# rp2040 register map
Vendor: Raspberry Pi; File version: 0.1
CPU: CM0PLUS r0p1, little endian, MPU, no FPU, VTOR, 2 interrupt priority bits, 26 interrupts
Registers are 32-bit, read-write, reset 0x0 unless marked. A register's access mark holds for its fields unless they carry their own. Offsets are from the block's base; [hi:lo] are bit positions; {n}, {i} and the like mark numbered series; 'fields as' and 'values as' point back to an identical list.

## SYSCFG — Register block for various chip control signals
Base 0x40004000
0x00 PROC0_NMI_MASK — Processor core 0 NMI source mask. Set a bit high to enable NMI from that IRQ
0x04 PROC1_NMI_MASK — Processor core 1 NMI source mask. Set a bit high to enable NMI from that IRQ
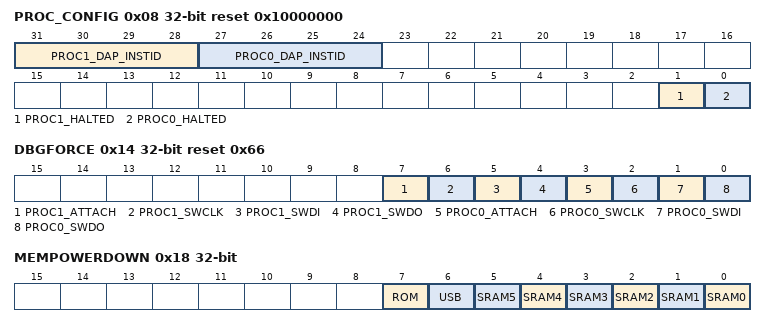
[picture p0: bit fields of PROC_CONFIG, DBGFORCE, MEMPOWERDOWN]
0x08 PROC_CONFIG access per field reset 0x10000000 — Configuration for processors
  [31:28] PROC1_DAP_INSTID rw — Configure proc1 DAP instance ID. Recommend that this is NOT changed until you require debug access in multi-chip environment. WARNING: do not set to 15 as this is reserved for RescueDP
  [27:24] PROC0_DAP_INSTID rw — Configure proc0 DAP instance ID. Recommend that this is NOT changed until you require debug access in multi-chip environment. WARNING: do not set to 15 as this is reserved for RescueDP
  [1] PROC1_HALTED ro — Indication that proc1 has halted
  [0] PROC0_HALTED ro — Indication that proc0 has halted
0x0C PROC_IN_SYNC_BYPASS — For each bit, if 1, bypass the input synchronizer between that GPIO and the GPIO input register in the SIO. The input synchronizers should generally be unbypassed, to avoid injecting metastabilities into processors. If you're feeling brave, you can bypass to save two cycles of input latency. This register applies to GPIO 0...29.
  [29:0] PROC_IN_SYNC_BYPASS
0x10 PROC_IN_SYNC_BYPASS_HI — For each bit, if 1, bypass the input synchronizer between that GPIO and the GPIO input register in the SIO. The input synchronizers should generally be unbypassed, to avoid injecting metastabilities into processors. If you're feeling brave, you can bypass to save two cycles of input latency. This register applies to GPIO 30...35 (the QSPI IOs).
  [5:0] PROC_IN_SYNC_BYPASS_HI
0x14 DBGFORCE access per field reset 0x66 — Directly control the SWD debug port of either processor
  [7] PROC1_ATTACH rw — Attach processor 1 debug port to syscfg controls, and disconnect it from external SWD pads.
  [6] PROC1_SWCLK rw — Directly drive processor 1 SWCLK, if PROC1_ATTACH is set
  [5] PROC1_SWDI rw — Directly drive processor 1 SWDIO input, if PROC1_ATTACH is set
  [4] PROC1_SWDO ro — Observe the value of processor 1 SWDIO output.
  [3] PROC0_ATTACH rw — Attach processor 0 debug port to syscfg controls, and disconnect it from external SWD pads.
  [2] PROC0_SWCLK rw — Directly drive processor 0 SWCLK, if PROC0_ATTACH is set
  [1] PROC0_SWDI rw — Directly drive processor 0 SWDIO input, if PROC0_ATTACH is set
  [0] PROC0_SWDO ro — Observe the value of processor 0 SWDIO output.
0x18 MEMPOWERDOWN — Control power downs to memories. Set high to power down memories. Use with extreme caution
  [7] ROM, [6] USB, [n] SRAM{n} (n=0..5)

## RESETS
Base 0x4000C000
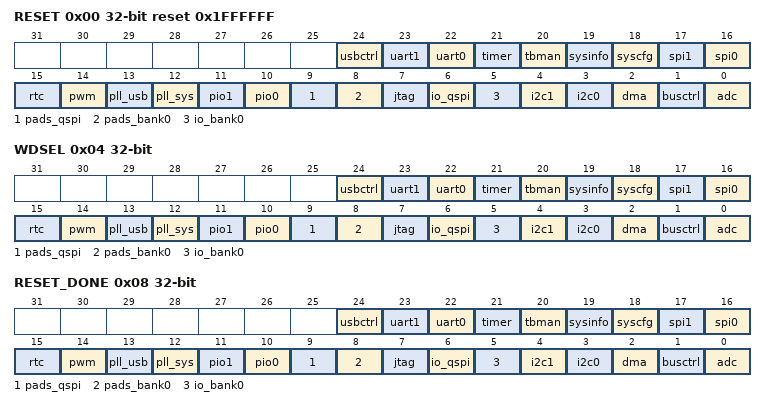
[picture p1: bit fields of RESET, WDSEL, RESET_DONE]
0x00 RESET reset 0x1FFFFFF — Reset control. If a bit is set it means the peripheral is in reset. 0 means the peripheral's reset is deasserted.
  [24] usbctrl, [23] uart1, [22] uart0, [21] timer, [20] tbman, [19] sysinfo, [18] syscfg, [17] spi1, [16] spi0, [15] rtc, [14] pwm, [13] pll_usb, [12] pll_sys, [11] pio1, [10] pio0, [9] pads_qspi, [8] pads_bank0, [7] jtag, [6] io_qspi, [5] io_bank0, [4] i2c1, [3] i2c0, [2] dma, [1] busctrl, [0] adc
0x04 WDSEL — Watchdog select. If a bit is set then the watchdog will reset this peripheral when the watchdog fires.
  fields as RESET
0x08 RESET_DONE ro — Reset done. If a bit is set then a reset done signal has been returned by the peripheral. This indicates that the peripheral's registers are ready to be accessed.
  fields as RESET

## PSM
Base 0x40010000
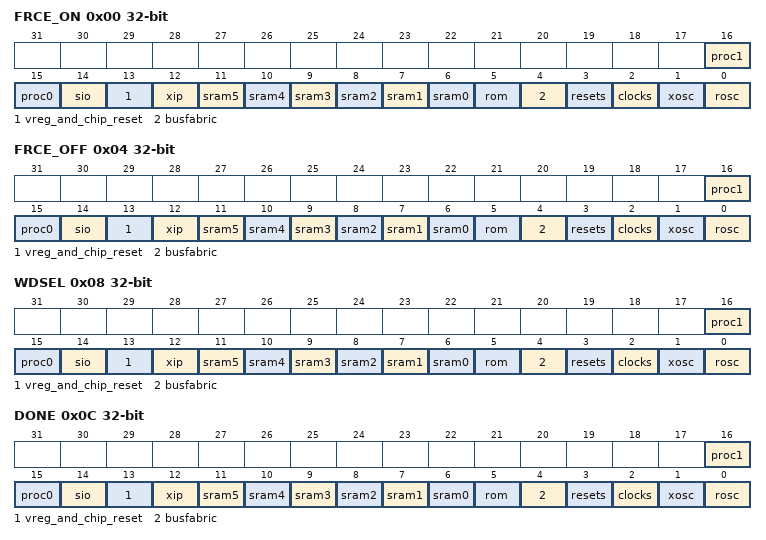
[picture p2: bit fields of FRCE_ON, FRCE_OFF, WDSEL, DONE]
0x00 FRCE_ON — Force block out of reset (i.e. power it on)
  [16] proc1, [15] proc0, [14] sio, [13] vreg_and_chip_reset, [12] xip, [n+6] sram{n} (n=0..5), [5] rom, [4] busfabric, [3] resets, [2] clocks, [1] xosc, [0] rosc
0x04 FRCE_OFF — Force into reset (i.e. power it off)
  fields as FRCE_ON
0x08 WDSEL — Set to 1 if this peripheral should be reset when the watchdog fires.
  fields as FRCE_ON
0x0C DONE ro — Indicates the peripheral's registers are ready to access.
  fields as FRCE_ON

## Notices in the file
Copyright (c) 2020 Raspberry Pi (Trading) Ltd.
SPDX-License-Identifier: BSD-3-Clause
